# STM32L4x5 register map
File version: 1.8
CPU: CM4 r0p1, little endian, MPU, FPU, 4 interrupt priority bits
Registers are 32-bit, read-write, reset 0x0 unless marked. A register's access mark holds for its fields unless they carry their own. Offsets are from the block's base; [hi:lo] are bit positions; 'fields as' and 'values as' point back to an identical list; <NAME> marks a mode.

## OPAMP — Operational amplifiers
Base 0x40007800
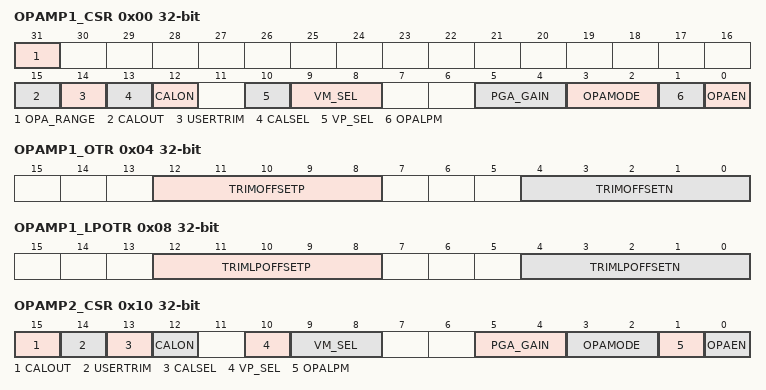
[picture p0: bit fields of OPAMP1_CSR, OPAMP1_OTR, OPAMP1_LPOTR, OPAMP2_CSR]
0x00 OPAMP1_CSR — OPAMP1 control/status register
  [31] OPA_RANGE — Operational amplifier power supply range for stability
    0=LOW (low range (VDDA < 2.4V); 1=HIGH (low range (VDDA >2.4V)
  [15] CALOUT — Operational amplifier calibration output
  [14] USERTRIM — allows to switch from AOP offset trimmed values to AOP offset
    0=Factory trim used; 1=User trim used
  [13] CALSEL — Calibration selection
    0=NMOS (0.2V applied to OPAMP inputs during calibration); 1=PMOS (VDDA-0.2V applied to OPAMP inputs during calibration")
  [12] CALON — Calibration mode enabled
    0=Disabled (Normal mode); 1=Enabled (Calibration mode)
  [10] VP_SEL — Non inverted input selection
    0=GPIO (GPIO connected to VINP); 1=DAC (DAC connected to VPINP)
  [9:8] VM_SEL — Inverting input selection
    0=GPIO (GPIO connectet to VINM); 1=LOW_LEAKAGE (Low leakage inputs connected (only available in certein BGA cases); 2=PGA_MODE (OPAMP in PGA mode)
  [5:4] PGA_GAIN — Operational amplifier Programmable amplifier gain value
    0=Gain2; 1=Gain4; 2=Gain8; 3=Gain16
  [3:2] OPAMODE — Operational amplifier PGA mode
    0=PGA_DISABLED (internal PGA diabled); 2=PGA_ENABLED (internal PGA enabled, gain programmed in PGA_GAIN); 3=FOLLOWER (internal follower)
  [1] OPALPM — Operational amplifier Low Power Mode
    0=NORMAL (OpAmp in normal mode); 1=LOW (OpAmp in low power mode)
  [0] OPAEN — Operational amplifier Enable
    0=Disabled (OpAmp disabled); 1=Enabled (OpAmp enabled)
0x04 OPAMP1_OTR — OPAMP1 offset trimming register in normal mode
  [12:8] TRIMOFFSETP — Trim for PMOS differential pairs
  [4:0] TRIMOFFSETN — Trim for NMOS differential pairs
0x08 OPAMP1_LPOTR — OPAMP1 offset trimming register in low-power mode
  [12:8] TRIMLPOFFSETP — Trim for PMOS differential pairs
  [4:0] TRIMLPOFFSETN — Trim for NMOS differential pairs
0x10 OPAMP2_CSR — OPAMP2 control/status register
  [15] CALOUT — Operational amplifier calibration output
  [14] USERTRIM — allows to switch from AOP offset trimmed values to AOP offset
    0=Factory trim used; 1=User trim used
  [13] CALSEL — Calibration selection
    values as OPAMP1_CSR.CALSEL
  [12] CALON — Calibration mode enabled
    0=Disabled (Normal mode); 1=Enabled (Calibration mode)
  [10] VP_SEL — Non inverted input selection
    values as OPAMP1_CSR.VP_SEL
  [9:8] VM_SEL — Inverting input selection
    values as OPAMP1_CSR.VM_SEL
  [5:4] PGA_GAIN — Operational amplifier Programmable amplifier gain value
    0=Gain2; 1=Gain4; 2=Gain8; 3=Gain16
  [3:2] OPAMODE — Operational amplifier PGA mode
    values as OPAMP1_CSR.OPAMODE
  [1] OPALPM — Operational amplifier Low Power Mode
    values as OPAMP1_CSR.OPALPM
  [0] OPAEN — Operational amplifier Enable
    0=Disabled (OpAmp disabled); 1=Enabled (OpAmp enabled)
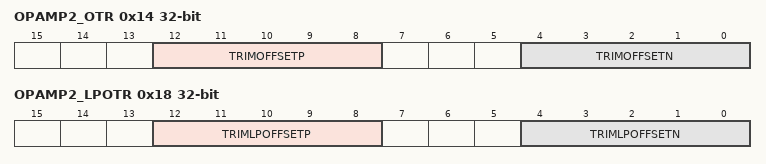
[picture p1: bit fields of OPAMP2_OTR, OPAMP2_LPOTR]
0x14 OPAMP2_OTR — OPAMP2 offset trimming register in normal mode
  fields as OPAMP1_OTR
0x18 OPAMP2_LPOTR — OPAMP2 offset trimming register in low-power mode
  fields as OPAMP1_LPOTR

## CRS — Clock recovery system
Base 0x40006000
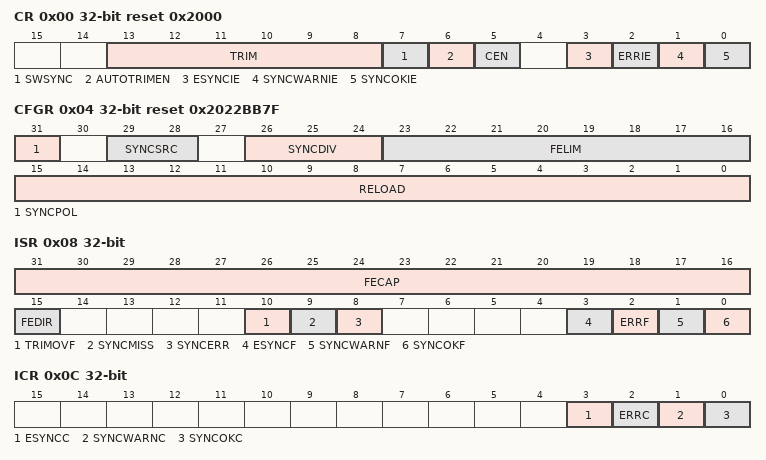
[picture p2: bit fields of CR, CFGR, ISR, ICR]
0x00 CR reset 0x2000 — control register
  [13:8] TRIM — HSI48 oscillator smooth trimming
  [7] SWSYNC — Generate software SYNC event
    1=Sync (A software sync is generated)
  [6] AUTOTRIMEN — Automatic trimming enable
    0=Disabled (Automatic trimming disabled); 1=Enabled (Automatic trimming enabled)
  [5] CEN — Frequency error counter enable
    0=Disabled (Frequency error counter disabled); 1=Enabled (Frequency error counter enabled)
  [3] ESYNCIE — Expected SYNC interrupt enable
    0=Disabled (Interrupt disabled); 1=Enabled (Interrupt enabled)
  [2] ERRIE — Synchronization or trimming error interrupt enable
    values as ESYNCIE
  [1] SYNCWARNIE — SYNC warning interrupt enable
    values as ESYNCIE
  [0] SYNCOKIE — SYNC event OK interrupt enable
    values as ESYNCIE
0x04 CFGR reset 0x2022BB7F — configuration register
  [31] SYNCPOL — SYNC polarity selection
    0=RisingEdge (SYNC active on rising edge); 1=FallingEdge (SYNC active on falling edge)
  [29:28] SYNCSRC — SYNC signal source selection
    0=GPIO_AF (GPIO AF (crs_sync_in_1) selected as SYNC signal source); 1=LSE (LSE (crs_sync_in_2) selected as SYNC signal source); 2=USB_SOF (USB SOF (crs_sync_in_3) selected as SYNC signal source)
  [26:24] SYNCDIV — SYNC divider
    0=Div1 (SYNC not divided); 1=Div2 (SYNC divided by 2); 2=Div4 (SYNC divided by 4); 3=Div8 (SYNC divided by 8); 4=Div16 (SYNC divided by 16); 5=Div32 (SYNC divided by 32); 6=Div64 (SYNC divided by 64); 7=Div128 (SYNC divided by 128)
  [23:16] FELIM — Frequency error limit
  [15:0] RELOAD — Counter reload value
0x08 ISR ro — interrupt and status register
  [31:16] FECAP — Frequency error capture
  [15] FEDIR — Frequency error direction
    0=UpCounting (Error in up-counting direction); 1=DownCounting (Error in down-counting direction)
  [10] TRIMOVF — Trimming overflow or underflow
    0=NotSignaled (Signal not set); 1=Signaled (Signal set)
  [9] SYNCMISS — SYNC missed
    0=NotSignaled (Signal not set); 1=Signaled (Signal set)
  [8] SYNCERR — SYNC error
    0=NotSignaled (Signal not set); 1=Signaled (Signal set)
  [3] ESYNCF — Expected SYNC flag
    0=NotSignaled (Signal not set); 1=Signaled (Signal set)
  [2] ERRF — Error flag
    0=NotSignaled (Signal not set); 1=Signaled (Signal set)
  [1] SYNCWARNF — SYNC warning flag
    0=NotSignaled (Signal not set); 1=Signaled (Signal set)
  [0] SYNCOKF — SYNC event OK flag
    0=NotSignaled (Signal not set); 1=Signaled (Signal set)
0x0C ICR — interrupt flag clear register
  [all] fields
    1=Clear flag
  [3] ESYNCC — Expected SYNC clear flag
  [2] ERRC — Error clear flag
  [1] SYNCWARNC — SYNC warning clear flag
  [0] SYNCOKC — SYNC event OK clear flag

## DBGMCU — Debug support
Base 0xE0042000
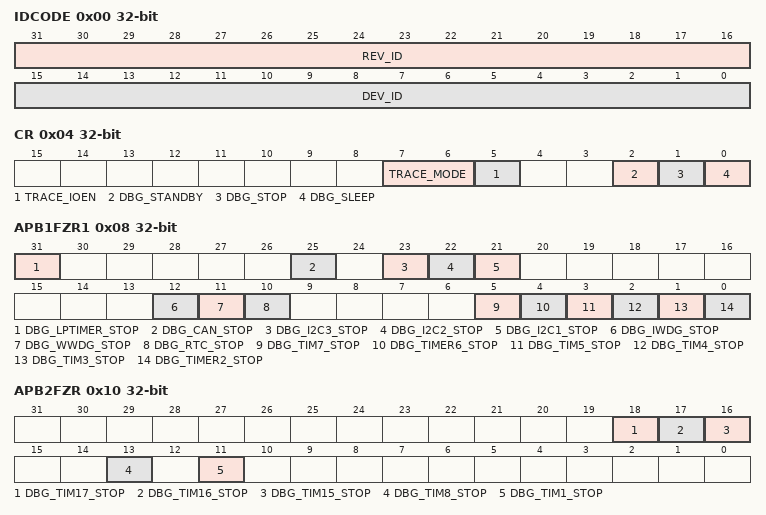
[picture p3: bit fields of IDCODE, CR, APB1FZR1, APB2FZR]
0x00 IDCODE ro — MCU Device ID Code Register
  [31:16] REV_ID — Revision Identifier
  [15:0] DEV_ID — Device Identifier
0x04 CR — Debug MCU Configuration Register
  [7:6] TRACE_MODE — Trace pin assignment control
  [5] TRACE_IOEN — Trace pin assignment control
  [2] DBG_STANDBY — Debug Standby Mode
  [1] DBG_STOP — Debug Stop Mode
  [0] DBG_SLEEP — Debug Sleep Mode
0x08 APB1FZR1 — APB Low Freeze Register 1
  [31] DBG_LPTIMER_STOP — LPTIM1 counter stopped when core is halted
  [25] DBG_CAN_STOP — bxCAN stopped when core is halted
  [23] DBG_I2C3_STOP — I2C3 SMBUS timeout counter stopped when core is halted
  [22] DBG_I2C2_STOP — I2C2 SMBUS timeout mode stopped when core is halted
  [21] DBG_I2C1_STOP — I2C1 SMBUS timeout mode stopped when core is halted
  [12] DBG_IWDG_STOP — Debug Independent Wachdog stopped when Core is halted
  [11] DBG_WWDG_STOP — Debug Window Wachdog stopped when Core is halted
  [10] DBG_RTC_STOP — Debug RTC stopped when Core is halted
  [5] DBG_TIM7_STOP — TIM7 counter stopped when core is halted
  [4] DBG_TIMER6_STOP — Debug Timer 6 stopped when Core is halted
  [3] DBG_TIM5_STOP — TIM5 counter stopped when core is halted
  [2] DBG_TIM4_STOP — TIM4 counter stopped when core is halted
  [1] DBG_TIM3_STOP — TIM3 counter stopped when core is halted
  [0] DBG_TIMER2_STOP — Debug Timer 2 stopped when Core is halted
0x0C APB1FZR2 — APB Low Freeze Register 2
  [5] DBG_LPTIM2_STOP — LPTIM2 counter stopped when core is halted
0x10 APB2FZR — APB High Freeze Register
  [18] DBG_TIM17_STOP — TIM17 counter stopped when core is halted
  [17] DBG_TIM16_STOP — TIM16 counter stopped when core is halted
  [16] DBG_TIM15_STOP — TIM15 counter stopped when core is halted
  [13] DBG_TIM8_STOP — TIM8 counter stopped when core is halted
  [11] DBG_TIM1_STOP — TIM1 counter stopped when core is halted
